# max32630 register map
Vendor: Maxim Integrated; Series: ARMCM4; File version: 1.1
CPU: CM4 r1p0, little endian, no MPU, FPU, 3 interrupt priority bits
Registers are 32-bit, read-write, reset 0x0 unless marked. A register's access mark holds for its fields unless they carry their own. Offsets are from the block's base; [hi:lo] are bit positions; {n}, {i} and the like mark numbered series; 'fields as' and 'values as' point back to an identical list.

## SPIX — SPI XIP Interface
Base 0x40004000
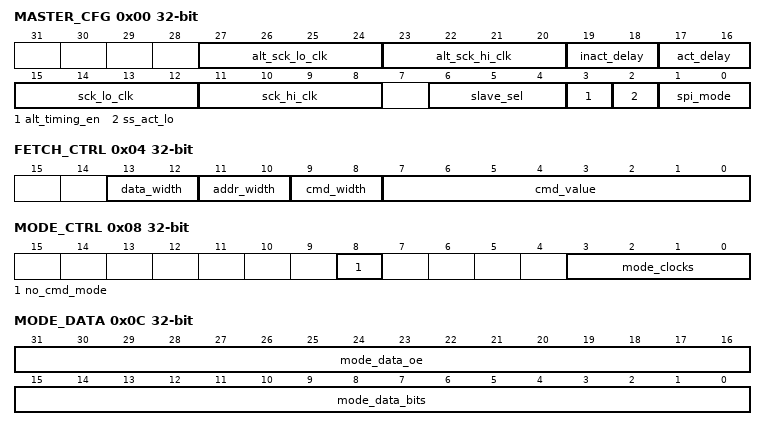
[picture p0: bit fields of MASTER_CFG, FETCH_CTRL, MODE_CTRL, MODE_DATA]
0x00 MASTER_CFG — SPIX Master Configuration
  [27:24] alt_sck_lo_clk — Alt SCK Low Clocks
  [23:20] alt_sck_hi_clk — Alt SCK High Clocks
  [19:18] inact_delay — SS Inactive Timing
    0=OFF (No SS Active timing delay enabled.); 1=FOR_2_MOD_CLK (SS Active timing delay of 2 SPIX module clock cycles.); 2=FOR_4_MOD_CLK (SS Active timing delay of 4 SPIX module clock cycles.); 3=FOR_8_MOD_CLK (SS Active timing delay of 8 SPIX module clock cycles.)
  [17:16] act_delay — SS Active Timing
    values as inact_delay
  [15:12] sck_lo_clk — SCK Low Clocks
  [11:8] sck_hi_clk — SCK High Clocks
  [6:4] slave_sel — SPIX Slave Select
  [3] alt_timing_en — Alternate Timing Mode Enable
    0=DISABLED (Alternate timing is disabled.); 1=ENABLED_AS_NEEDED (Alternate timing will be enabled automatically when needed.)
  [2] ss_act_lo — SPIX Slave Select Polarity
    0=ACTIVE_HIGH (Enabled slave select (SS) is active high.); 1=ACTIVE_LOW (Enabled slave select (SS) is active low.)
  [1:0] spi_mode — SPIX Mode
    0=SCK_HI_SAMPLE_RISING (SCK is active high, data is sampled on clock rising edge.); 3=SCK_LO_SAMPLE_FALLING (SCK is active low, data is sampled on clock rising edge.)
0x04 FETCH_CTRL — SPIX Fetch Control
  [13:12] data_width
    0=SINGLE (Single I/O used for Tx/Rx.); 1=DUAL_IO (Dual I/O lines used for Tx/Rx.); 2=QUAD_IO (Quad I/O lines used for Tx/Rx.)
  [11:10] addr_width — Address Width
    values as data_width
  [9:8] cmd_width — Command Width
    values as data_width
  [7:0] cmd_value — Command Value
0x08 MODE_CTRL — SPIX Mode Control
  [8] no_cmd_mode — No Command Mode
  [3:0] mode_clocks
0x0C MODE_DATA — SPIX Mode Data
  [31:16] mode_data_oe — Mode Output Enable
  [15:0] mode_data_bits — Mode Data

## PMU0 — Peripheral Management Unit
Base 0x40005000
Same registers: PMU1 0x40005020, PMU2 0x40005040, PMU3 0x40005060, PMU4 0x40005080, PMU5 0x400050A0
0x00 DSCADR — Starting Descriptor Address
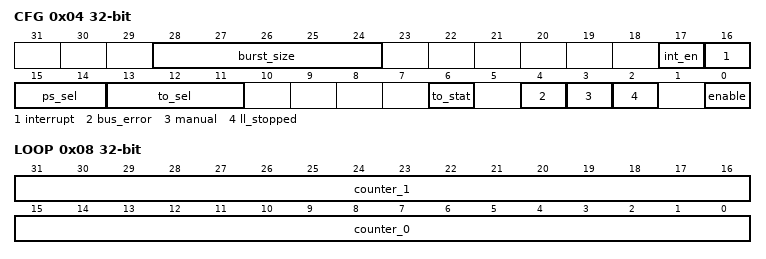
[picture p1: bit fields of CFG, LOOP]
0x04 CFG — Channel Configuration
  [28:24] burst_size — DMA Maximum Burst Size
  [17] int_en — PMU Channel Interrupt Enable
  [16] interrupt write-1-clears — Descriptor Interrupt Flag
  [15:14] ps_sel — Time Out Interval Prescale Select
  [13:11] to_sel — Time Out Interval Select
  [6] to_stat write-1-clears — AHB Bus Timeout Interrupt Flag
  [4] bus_error write-1-clears — AHB Bus Error Interrupt Flag
  [3] manual — Manual Mode Enable
  [2] ll_stopped — Linked List Engine Status
  [0] enable — PMU Channel Enable
0x08 LOOP — Channel Loop Counters
  [31:16] counter_1 — CH1 Loop Counter 0
  [15:0] counter_0 — CH1 Loop Counter 1
0x0C OP — Current Descriptor DWORD 0 (OP)
{0xC+4i} DSC{i} (i=1..4) — Current Descriptor DWORD {i}

## CRC — CRC-16/CRC-32 Engine
Base 0x40006000
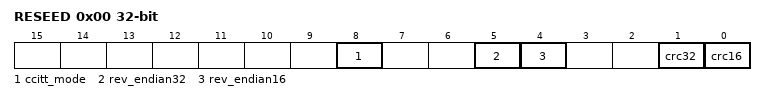
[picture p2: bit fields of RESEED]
0x00 RESEED — CRC-16/CRC-32 Reseed Controls
  [8] ccitt_mode — CRC16-CCITT Mode
  [5] rev_endian32 — Reverse Endianness for CRC32
  [4] rev_endian16 — Reverse Endianness for CRC16
  [1] crc32 write-1-clears — Reseed CRC32 Generator
  [0] crc16 write-1-clears — Reseed CRC16 Generator
0x04 SEED16 — Reseed Value for CRC-16 Calculations
0x08 SEED32 — Reseed Value for CRC-32 Calculations

## TPU — Trust Protection Unit (TPU)
Base 0x40007000
0x00 PRNG_USER_ENTROPY — PRNG User Entropy Value
0x04 PRNG_RND_NUM — PRNG Random Number Output

## TPU_TSR — Trust Protection Unit (TPU)
Base 0x40007C00
{0x10+4i} SKS{i} (i=0..3) — TPU Secure Key Storage Register {i} (Cleared on Tamper Detect)

## AES — AES Cryptographic Engine
Base 0x40007400
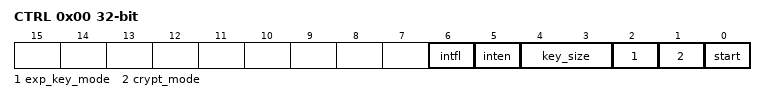
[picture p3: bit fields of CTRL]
0x00 CTRL — AES Control and Status
  [6] intfl write-1-clears — AES Interrupt Flag
  [5] inten — AES Interrupt Enable
  [4:3] key_size — AES Key Size Select
    0=Use 128-bit AES key size; 1=Use 192-bit AES key size; 2=Use 256-bit AES key size
  [2] exp_key_mode — AES Expanded Key Mode
    0=CALC_NEW_EXP_KEY (Calculate new expanded key for this operation.); 1=USE_LAST_EXP_KEY (Use expanded key calculated by the last operation.)
  [1] crypt_mode — AES Encrypt/Decrypt Mode
    0=ENCRYPT_MODE (Perform AES encryption operation.); 1=DECRYPT_MODE (Perform AES decryption operation.)
  [0] start — AES Start/Busy
0x08 ERASE_ALL wo — A write to this location triggers an erase of all AES memory locations.
